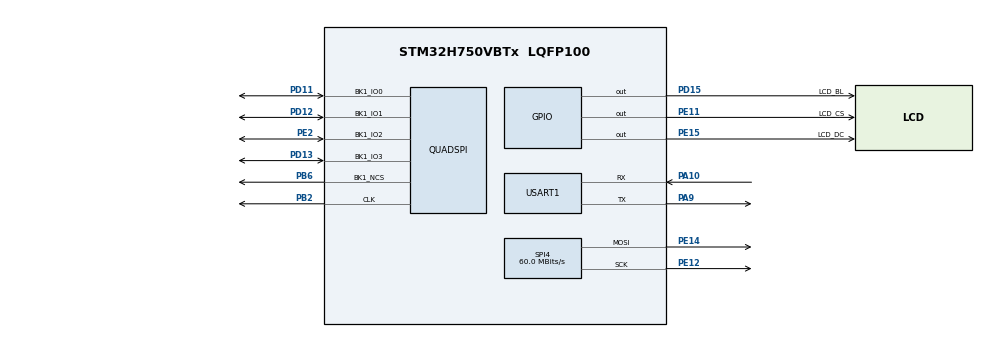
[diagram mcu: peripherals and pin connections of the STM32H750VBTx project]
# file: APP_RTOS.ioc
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CORTEX_M7.default_mode_Activation=1
Dma.Request0=USART1_TX
Dma.Request1=SPI4_TX
Dma.SPI4_TX.1.Direction=DMA_MEMORY_TO_PERIPH
Dma.SPI4_TX.1.EventEnable=DISABLE
Dma.SPI4_TX.1.FIFOMode=DMA_FIFOMODE_DISABLE
Dma.SPI4_TX.1.Instance=DMA1_Stream1
Dma.SPI4_TX.1.MemDataAlignment=DMA_MDATAALIGN_HALFWORD
Dma.SPI4_TX.1.MemInc=DMA_MINC_ENABLE
Dma.SPI4_TX.1.Mode=DMA_NORMAL
Dma.SPI4_TX.1.PeriphDataAlignment=DMA_PDATAALIGN_HALFWORD
Dma.SPI4_TX.1.PeriphInc=DMA_PINC_DISABLE
Dma.SPI4_TX.1.Polarity=HAL_DMAMUX_REQ_GEN_RISING
Dma.SPI4_TX.1.Priority=DMA_PRIORITY_VERY_HIGH
Dma.SPI4_TX.1.RequestNumber=1
Dma.SPI4_TX.1.SignalID=NONE
Dma.SPI4_TX.1.SyncEnable=DISABLE
Dma.SPI4_TX.1.SyncPolarity=HAL_DMAMUX_SYNC_NO_EVENT
Dma.SPI4_TX.1.SyncRequestNumber=1
Dma.SPI4_TX.1.SyncSignalID=NONE
Dma.USART1_TX.0.Direction=DMA_MEMORY_TO_PERIPH
Dma.USART1_TX.0.EventEnable=DISABLE
Dma.USART1_TX.0.FIFOMode=DMA_FIFOMODE_DISABLE
Dma.USART1_TX.0.Instance=DMA1_Stream0
Dma.USART1_TX.0.MemDataAlignment=DMA_MDATAALIGN_BYTE
Dma.USART1_TX.0.MemInc=DMA_MINC_ENABLE
Dma.USART1_TX.0.Mode=DMA_NORMAL
Dma.USART1_TX.0.PeriphDataAlignment=DMA_PDATAALIGN_BYTE
Dma.USART1_TX.0.PeriphInc=DMA_PINC_DISABLE
Dma.USART1_TX.0.Polarity=HAL_DMAMUX_REQ_GEN_RISING
Dma.USART1_TX.0.Priority=DMA_PRIORITY_VERY_HIGH
Dma.USART1_TX.0.RequestNumber=1
Dma.USART1_TX.0.SignalID=NONE
Dma.USART1_TX.0.SyncEnable=DISABLE
Dma.USART1_TX.0.SyncPolarity=HAL_DMAMUX_SYNC_NO_EVENT
Dma.USART1_TX.0.SyncRequestNumber=1
Dma.USART1_TX.0.SyncSignalID=NONE
FREERTOS.Tasks01=defaultTask,24,128,StartDefaultTask,Default,NULL,Dynamic,NULL,NULL
Mcu.Family=STM32H7
Mcu.Name=STM32H750VBTx
Mcu.Package=LQFP100
NVIC.DMA1_Stream0_IRQn=true\:5\:0\:false\:false\:true\:true\:false\:true\:true
NVIC.DMA1_Stream1_IRQn=true\:5\:0\:false\:false\:true\:true\:false\:true\:true
NVIC.PriorityGroup=NVIC_PRIORITYGROUP_4
NVIC.SPI4_IRQn=true\:5\:0\:false\:false\:true\:true\:false\:true\:true
NVIC.TIM6_DAC_IRQn=true\:15\:0\:false\:false\:true\:false\:false\:true\:true
NVIC.TimeBase=TIM6_DAC_IRQn
NVIC.TimeBaseIP=TIM6
PA10.Mode=Asynchronous
PA10.Signal=USART1_RX
PA13\ (JTMS/SWDIO).Mode=Serial_Wire
PA13\ (JTMS/SWDIO).Signal=DEBUG_JTMS-SWDIO
PA14\ (JTCK/SWCLK).Mode=Serial_Wire
PA14\ (JTCK/SWCLK).Signal=DEBUG_JTCK-SWCLK
PA9.Mode=Asynchronous
PA9.Signal=USART1_TX
PB2.Mode=Single Bank 1
PB2.Signal=QUADSPI_CLK
PB6.Mode=Single Bank 1
PB6.Signal=QUADSPI_BK1_NCS
PD11.Mode=Single Bank 1
PD11.Signal=QUADSPI_BK1_IO0
PD12.Mode=Single Bank 1
PD12.Signal=QUADSPI_BK1_IO1
PD13.Mode=Single Bank 1
PD13.Signal=QUADSPI_BK1_IO3
PD15.GPIO_Label=LCD_BL
PD15.Signal=GPIO_Output
PE11.GPIO_Label=LCD_CS
PE11.Signal=GPIO_Output
PE12.Mode=TX_Only_Simplex_Unidirect_Master
PE12.Signal=SPI4_SCK
PE14.Mode=TX_Only_Simplex_Unidirect_Master
PE14.Signal=SPI4_MOSI
PE15.GPIO_Label=LCD_DC
PE15.Signal=GPIO_Output
PE2.Mode=Single Bank 1
PE2.Signal=QUADSPI_BK1_IO2
PH0-OSC_IN\ (PH0).Mode=HSE-External-Oscillator
PH0-OSC_IN\ (PH0).Signal=RCC_OSC_IN
PH1-OSC_OUT\ (PH1).Mode=HSE-External-Oscillator
PH1-OSC_OUT\ (PH1).Signal=RCC_OSC_OUT
ProjectManager.HeapSize=0x200
ProjectManager.StackSize=0x400
ProjectManager.TargetToolchain=CMake
QUADSPI.ClockPrescaler=2
QUADSPI.FifoThreshold=32
QUADSPI.FlashSize=22
QUADSPI.SampleShifting=QSPI_SAMPLE_SHIFTING_HALFCYCLE
RCC.ADCFreq_Value=50390625
RCC.APB1Freq_Value=120000000
RCC.APB2Freq_Value=120000000
RCC.APB3Freq_Value=120000000
RCC.APB4Freq_Value=120000000
RCC.CortexFreq_Value=480000000
RCC.D1PPRE=RCC_APB3_DIV2
RCC.D2PPRE1=RCC_APB1_DIV2
RCC.D2PPRE2=RCC_APB2_DIV2
RCC.D3PPRE=RCC_APB4_DIV2
RCC.DIVM1=5
RCC.DIVN1=192
RCC.DIVR1=5
RCC.HCLKFreq_Value=240000000
RCC.HPRE=RCC_HCLK_DIV2
RCC.PLL2FRACN=0
RCC.PLL3FRACN=0
RCC.PLLFRACN=0
RCC.PLLSourceVirtual=RCC_PLLSOURCE_HSE
RCC.SYSCLKFreq_VALUE=480000000
RCC.SYSCLKSource=RCC_SYSCLKSOURCE_PLLCLK
RCC.USBFreq_Value=480000000
SPI4.CalculateBaudRate=60.0 MBits/s
SPI4.Direction=SPI_DIRECTION_2LINES_TXONLY
SPI4.Mode=SPI_MODE_MASTER
SPI4.VirtualType=VM_MASTER
USART1.VirtualMode-Asynchronous=VM_ASYNC
VP_FREERTOS_VS_CMSIS_V2.Mode=CMSIS_V2
VP_MEMORYMAP_VS_MEMORYMAP.Mode=CurAppReg
VP_SYS_VS_tim6.Mode=TIM6
board=custom

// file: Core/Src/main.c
/* USER CODE BEGIN Header */
/**
  ******************************************************************************
  * @file           : main.c
  * @brief          : Main program body
  ******************************************************************************
  * @attention
  *
  * Copyright (c) 2025 STMicroelectronics.
  * All rights reserved.
  *
  * This software is licensed under terms that can be found in the LICENSE file
  * in the root directory of this software component.
  * If no LICENSE file comes with this software, it is provided AS-IS.
  *
  ******************************************************************************
  */
/* USER CODE END Header */
#include "main.h"
#include "cmsis_os.h"
#include "dma.h"
#include "quadspi.h"
#include "spi.h"
#include "usart.h"
#include "gpio.h"

/* USER CODE BEGIN Includes */
#include "app_main.h"
/* USER CODE END Includes */

void SystemClock_Config(void);
static void MPU_Config(void);
void MX_FREERTOS_Init(void);

int main(void)
{

  /* MPU Configuration--------------------------------------------------------*/
  MPU_Config();

  /* MCU Configuration--------------------------------------------------------*/

  /* Reset of all peripherals, Initializes the Flash interface and the Systick. */
  HAL_Init();

  /* Configure the system clock */
  // SystemClock_Config(); // 保持使用 Bootloader 配置的时钟
  SystemCoreClockUpdate(); // 更新全局时钟变量以匹配实际频率 (480MHz)

  /* Initialize all configured peripherals */
  MX_GPIO_Init();
  MX_DMA_Init();
  MX_USART1_UART_Init();
  // MX_QUADSPI_Init(); //  不要初始化！Bootloader已配置为Memory-Mapped模式
  MX_SPI4_Init();
  /* USER CODE BEGIN 2 */
  __enable_irq(); // 重新开启中断，Bootloader 跳转前关闭了它
  app_main_init();
  /* USER CODE END 2 */

  /* Init scheduler */
  osKernelInitialize();  /* Call init function for freertos objects (in cmsis_os2.c) */
  MX_FREERTOS_Init();

  /* Start scheduler */
  osKernelStart();

  /* We should never get here as control is now taken by the scheduler */

  /* Infinite loop */
  while (1)
  {

  }
}

void SystemClock_Config(void)
{
  RCC_OscInitTypeDef RCC_OscInitStruct = {0};
  RCC_ClkInitTypeDef RCC_ClkInitStruct = {0};

  /** Supply configuration update enable
  */
  HAL_PWREx_ConfigSupply(PWR_LDO_SUPPLY);

  /** Configure the main internal regulator output voltage
  */
  __HAL_PWR_VOLTAGESCALING_CONFIG(PWR_REGULATOR_VOLTAGE_SCALE0);

  while(!__HAL_PWR_GET_FLAG(PWR_FLAG_VOSRDY)) {}

  /** Initializes the RCC Oscillators according to the specified parameters
  * in the RCC_OscInitTypeDef structure.
  */
  RCC_OscInitStruct.OscillatorType = RCC_OSCILLATORTYPE_HSE;
  RCC_OscInitStruct.HSEState = RCC_HSE_ON;
  RCC_OscInitStruct.PLL.PLLState = RCC_PLL_ON;
  RCC_OscInitStruct.PLL.PLLSource = RCC_PLLSOURCE_HSE;
  RCC_OscInitStruct.PLL.PLLM = 5;
  RCC_OscInitStruct.PLL.PLLN = 192;
  RCC_OscInitStruct.PLL.PLLP = 2;
  RCC_OscInitStruct.PLL.PLLQ = 2;
  RCC_OscInitStruct.PLL.PLLR = 5;
  RCC_OscInitStruct.PLL.PLLRGE = RCC_PLL1VCIRANGE_2;
  RCC_OscInitStruct.PLL.PLLVCOSEL = RCC_PLL1VCOWIDE;
  RCC_OscInitStruct.PLL.PLLFRACN = 0;
  if (HAL_RCC_OscConfig(&RCC_OscInitStruct) != HAL_OK)
  {
    Error_Handler();
  }

  /** Initializes the CPU, AHB and APB buses clocks
  */
  RCC_ClkInitStruct.ClockType = RCC_CLOCKTYPE_HCLK|RCC_CLOCKTYPE_SYSCLK
                              |RCC_CLOCKTYPE_PCLK1|RCC_CLOCKTYPE_PCLK2
                              |RCC_CLOCKTYPE_D3PCLK1|RCC_CLOCKTYPE_D1PCLK1;
  RCC_ClkInitStruct.SYSCLKSource = RCC_SYSCLKSOURCE_PLLCLK;
  RCC_ClkInitStruct.SYSCLKDivider = RCC_SYSCLK_DIV1;
  RCC_ClkInitStruct.AHBCLKDivider = RCC_HCLK_DIV2;
  RCC_ClkInitStruct.APB3CLKDivider = RCC_APB3_DIV2;
  RCC_ClkInitStruct.APB1CLKDivider = RCC_APB1_DIV2;
  RCC_ClkInitStruct.APB2CLKDivider = RCC_APB2_DIV2;
  RCC_ClkInitStruct.APB4CLKDivider = RCC_APB4_DIV2;

  if (HAL_RCC_ClockConfig(&RCC_ClkInitStruct, FLASH_LATENCY_4) != HAL_OK)
  {
    Error_Handler();
  }
}

 /* MPU Configuration */

void MPU_Config(void)
{
  MPU_Region_InitTypeDef MPU_InitStruct = {0};

  /* Disables the MPU */
  HAL_MPU_Disable();

  /** Initializes and configures the Region and the memory to be protected
  */
  MPU_InitStruct.Enable = MPU_REGION_ENABLE;
  MPU_InitStruct.Number = MPU_REGION_NUMBER0;
  MPU_InitStruct.BaseAddress = 0x0;
  MPU_InitStruct.Size = MPU_REGION_SIZE_4GB;
  MPU_InitStruct.SubRegionDisable = 0x87;
  MPU_InitStruct.TypeExtField = MPU_TEX_LEVEL0;
  MPU_InitStruct.AccessPermission = MPU_REGION_NO_ACCESS;
  MPU_InitStruct.DisableExec = MPU_INSTRUCTION_ACCESS_DISABLE;
  MPU_InitStruct.IsShareable = MPU_ACCESS_SHAREABLE;
  MPU_InitStruct.IsCacheable = MPU_ACCESS_NOT_CACHEABLE;
  MPU_InitStruct.IsBufferable = MPU_ACCESS_NOT_BUFFERABLE;
  HAL_MPU_ConfigRegion(&MPU_InitStruct);

  /** Configure the MPU attributes for QSPI Flash (0x90000000)
   */
  MPU_InitStruct.Enable = MPU_REGION_ENABLE;
  MPU_InitStruct.Number = MPU_REGION_NUMBER1;
  MPU_InitStruct.BaseAddress = 0x90000000;
  MPU_InitStruct.Size = MPU_REGION_SIZE_8MB;
  MPU_InitStruct.SubRegionDisable = 0x0;
  MPU_InitStruct.TypeExtField = MPU_TEX_LEVEL0;
  MPU_InitStruct.AccessPermission = MPU_REGION_FULL_ACCESS;
  MPU_InitStruct.DisableExec = MPU_INSTRUCTION_ACCESS_ENABLE;
  MPU_InitStruct.IsShareable = MPU_ACCESS_NOT_SHAREABLE;
  MPU_InitStruct.IsCacheable = MPU_ACCESS_CACHEABLE;
  MPU_InitStruct.IsBufferable = MPU_ACCESS_BUFFERABLE;
  HAL_MPU_ConfigRegion(&MPU_InitStruct);

  /* Enables the MPU */
  HAL_MPU_Enable(MPU_PRIVILEGED_DEFAULT);

}

void HAL_TIM_PeriodElapsedCallback(TIM_HandleTypeDef *htim)
{
  if (htim->Instance == TIM6)
  {
    HAL_IncTick();
  }
}

void Error_Handler(void)
{
  __disable_irq();
  while (1)
  {
  }
}
